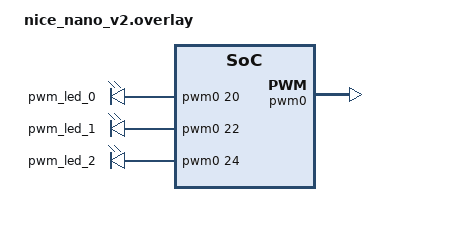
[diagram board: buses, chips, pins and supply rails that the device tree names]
#include <dt-bindings/led/led.h>

&pwm0 {
    status = "okay";
    ch0-pin = <20>; /* LED 0 */
    ch1-pin = <22>; /* LED 1 */
    ch2-pin = <24>; /* LED 2 */
};

/ {
    backlight: pwmleds {
        compatible = "pwm-leds";
        label = "Backlight LEDs";
        pwm_led_0 {
            pwms = <&pwm0 20>; /* LED 0 */
        };
        pwm_led_1 {
            pwms = <&pwm0 22>; /* LED 1 */
        };
        pwm_led_2 {
            pwms = <&pwm0 24>; /* LED 2 */
        };
    };
};


/ {
	chosen {
		 zmk,backlight = &backlight;
	};
};
